# STM32WB35xx register map
File version: 1.0
Registers are 32-bit, read-write, reset 0x0 unless marked. A register's access mark holds for its fields unless they carry their own. Offsets are from the block's base; [hi:lo] are bit positions; {n}, {i} and the like mark numbered series; 'fields as' and 'values as' point back to an identical list.

## DMAMUX1 — DMA Multiplexer
Base 0x40020800
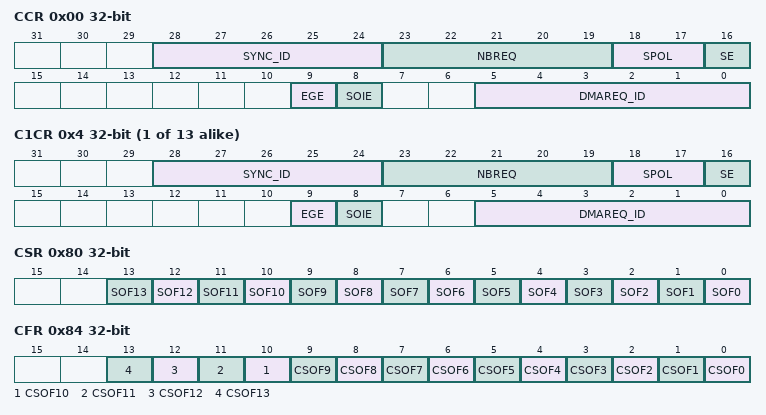
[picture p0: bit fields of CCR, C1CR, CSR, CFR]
0x00 CCR — DMA Multiplexer Channel x Control Register
  [28:24] SYNC_ID — Synchronization ID
  [23:19] NBREQ — Number of request
  [18:17] SPOL — Synchronization polarity
  [16] SE — Synchronization enable
  [9] EGE — Event generation interrupt enable
  [8] SOIE — Synchro overrun interrupt enable
  [5:0] DMAREQ_ID — DMA Request ID
{0x0+4i} C{i}CR (i=1..13) — DMA Multiplexer Channel x Control Register
  fields as CCR
0x80 CSR — DMA Channel Status Register
  [n] SOF{n} (n=0..13) — Synchronization Overrun Flag {n}
0x84 CFR — DMA Channel Clear Flag Register
  [n] CSOF{n} (n=0..13) — Clear Overrun Flag {n}
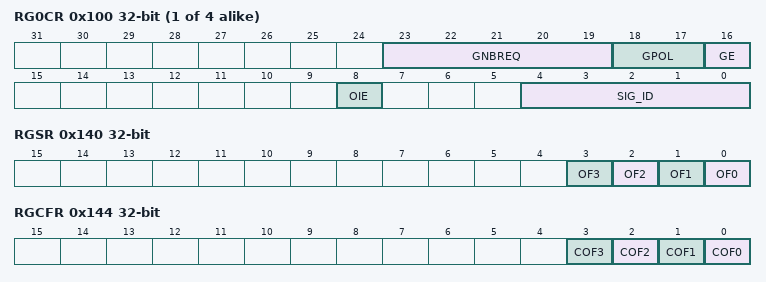
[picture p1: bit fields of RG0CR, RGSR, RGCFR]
{0x100+4i} RG{i}CR (i=0..3) — DMA Request Generator x Control Register
  [23:19] GNBREQ — Number of request
  [18:17] GPOL — Generation polarity
  [16] GE — Generation enable
  [8] OIE — Overrun interrupt enable
  [4:0] SIG_ID — Signal ID
0x140 RGSR — DMA Request Generator Status Register
  [n] OF{n} (n=0..3) — Overrun flag {n}
0x144 RGCFR — DMA Request Generator Clear Flag Register
  [n] COF{n} (n=0..3) — Clear Overrun flag {n}

## CRC — CRC calculation unit
Base 0x40023000
0x00 DR — CRC Data register
  [31:0] DR — Data register bits
0x04 IDR — CRC Independent data register
  [31:0] IDR — General-purpose 8-bits data register bits
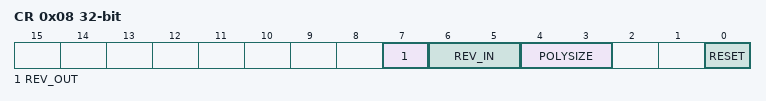
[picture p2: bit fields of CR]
0x08 CR — CRC Control register
  [7] REV_OUT — REV_OUT Reverse Output Data bits
    0=NONE (Output Data bit order not affected); 1=BIT (Output Data bit reversal done by bit)
  [6:5] REV_IN — REV_IN Reverse Input Data bits
    0=NONE (Input Data bit order not affected); 1=BYTE (Input Data bit reversal done by byte); 2=HALFWORD (Input Data bit reversal done by half-word); 3=WORD (Input Data bit reversal done by word)
  [4:3] POLYSIZE — Polynomial size bits
    0=POLYLENGTH_32B (32 bits Polynomial size); 1=POLYLENGTH_16B (16 bits Polynomial size); 2=POLYLENGTH_8B (8 bits Polynomial size); 3=POLYLENGTH_7B (7 bits Polynomial size)
  [0] RESET — RESET the CRC computation unit bit
0x10 INIT — Initial CRC value register
  [31:0] INIT — Initial CRC value bits
0x14 POL — CRC polynomial register
  [31:0] POL — Coefficients of the polynomial

## GPIOA — General Purpose I/O
Base 0x48000000
Same registers: GPIOB 0x48000400, GPIOC 0x48000800, GPIOE 0x48001000, GPIOH 0x48001C00
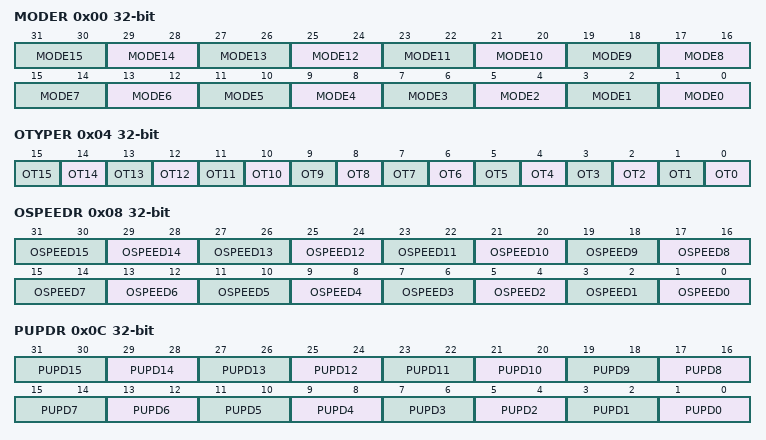
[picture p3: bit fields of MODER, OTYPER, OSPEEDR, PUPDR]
0x00 MODER — GPIO port mode register
  [2n+1:2n] MODE{n} (n=0..15)
0x04 OTYPER — GPIO port output type register
  [n] OT{n} (n=0..15)
0x08 OSPEEDR — GPIO port output speed register
  [2n+1:2n] OSPEED{n} (n=0..15)
0x0C PUPDR — GPIO port pull-up/pull-down register
  [2n+1:2n] PUPD{n} (n=0..15)
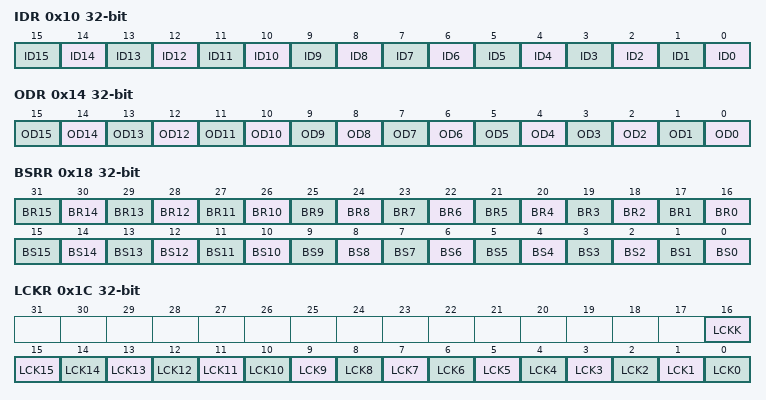
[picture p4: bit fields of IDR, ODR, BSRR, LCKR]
0x10 IDR — GPIO port input data register
  [n] ID{n} (n=0..15)
0x14 ODR — GPIO port output data register
  [n] OD{n} (n=0..15)
0x18 BSRR — GPIO port bit set/reset register
  [n+16] BR{n} (n=0..15), [n] BS{n} (n=0..15)
0x1C LCKR — GPIO port configuration lock register
  [16] LCKK, [n] LCK{n} (n=0..15)
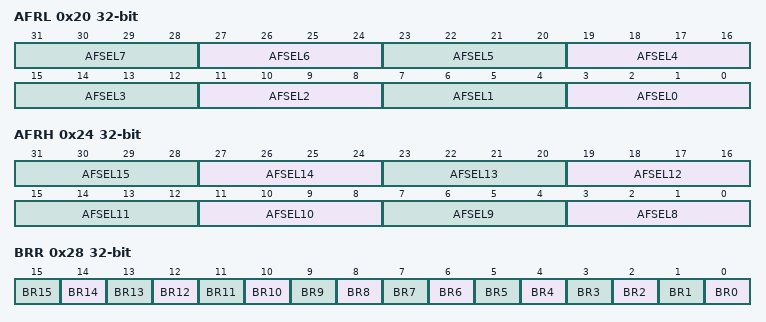
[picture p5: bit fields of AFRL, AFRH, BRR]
0x20 AFRL — GPIO alternate function registers
  [4n+3:4n] AFSEL{n} (n=0..7)
0x24 AFRH — GPIO alternate function registers
  [4n-29:4n-32] AFSEL{n} (n=8..15)
0x28 BRR — GPIO Bit Reset register
  [n] BR{n} (n=0..15)

## AES1 — AES hardware accelerator
Base 0x50060000
Same registers: AES2 0x58001800
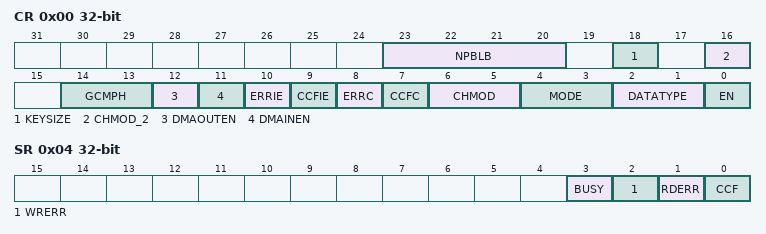
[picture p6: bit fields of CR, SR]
0x00 CR — AES control register
  [23:20] NPBLB — Number of padding bytes in last payload block
  [18] KEYSIZE — Key size selection
  [16] CHMOD_2 — AES Chaining Mode
  [14:13] GCMPH — GCM Phase
  [12] DMAOUTEN — Enable data output phase DMA management
  [11] DMAINEN — Enable data input phase DMA management
  [10] ERRIE — Error Interrupt Enable
  [9] CCFIE — Computation Complete Flag Interrupt Enable
  [8] ERRC — Error Clear
  [7] CCFC — Computation Complete Flag Clear
  [6:5] CHMOD — AES Chaining Mode
  [4:3] MODE — AES Mode Of Operation
  [2:1] DATATYPE — Data type selection
  [0] EN — AES Enable
0x04 SR — AES status register
  [3] BUSY — Busy Flag
  [2] WRERR — Write Error Flag
  [1] RDERR — Read Error Flag
  [0] CCF — Computation Complete Flag
0x08 DINR — AES data input register
  [31:0] DINR — AES Data Input Register
0x0C DOUTR — AES data output register
  [31:0] DOUTR — AES Data Output Register
{0x10+4i} KEYR{i} (i=0..3) — AES key register {i}
  [31:0] KEYR{i} — AES Key Register {i}
{0x20+4i} IVR{i} (i=0..3) — AES initialization vector register {i}
  [31:0] IVR{i} — AES Initialization Vector Register {i}
{0x20+4i} KEYR{i} (i=4..7) — AES key register {i}
  [31:0] KEYR{i} — AES Key Register {i}
{0x40+4i} SUSP{i}R (i=0..7) — AES Suspend register {i}
  [31:0] SUSP{i}R — AES Suspend registers {i}
